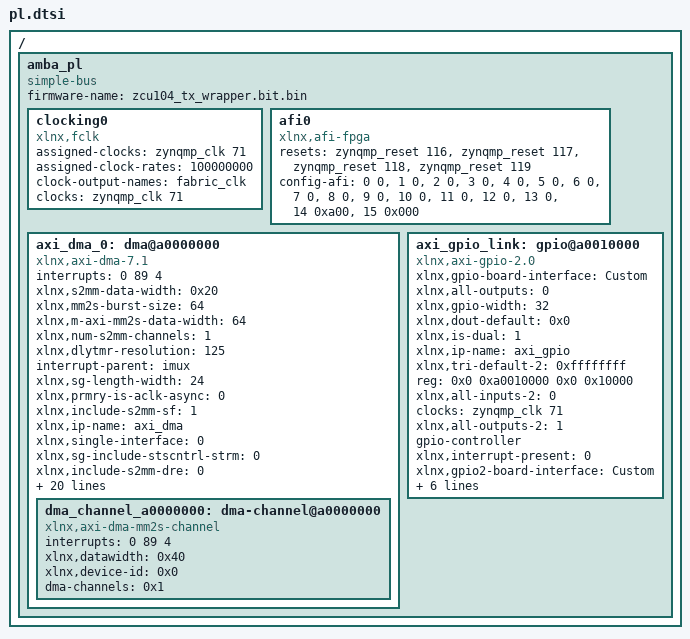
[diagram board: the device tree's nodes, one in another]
/ {
	amba_pl: amba_pl {
		ranges;
		compatible = "simple-bus";
		#address-cells = <2>;
		#size-cells = <2>;
		firmware-name = "zcu104_tx_wrapper.bit.bin";
		clocking0: clocking0 {
			compatible = "xlnx,fclk";
			status = "okay";
			assigned-clocks = <&zynqmp_clk 71>;
			assigned-clock-rates = <100000000>;
			#clock-cells = <0>;
			clock-output-names = "fabric_clk";
			clocks = <&zynqmp_clk 71>;
		};
		afi0: afi0 {
			status = "okay";
			compatible = "xlnx,afi-fpga";
			resets = <&zynqmp_reset 116>, <&zynqmp_reset 117>, <&zynqmp_reset 118>, <&zynqmp_reset 119>;
			config-afi = < 0 0>, <1 0>, <2 0>, <3 0>, <4 0>, <5 0>, <6 0>, <7 0>, <8 0>, <9 0>, <10 0>, <11 0>, <12 0>, <13 0>, <14 0xa00>, <15 0x000>;
		};
		axi_dma_0: dma@a0000000 {
			interrupts = < 0 89 4 >;
			compatible = "xlnx,axi-dma-7.1" , "xlnx,axi-dma-1.00.a";
			xlnx,s2mm-data-width = <0x20>;
			xlnx,mm2s-burst-size = <64>;
			xlnx,m-axi-mm2s-data-width = <64>;
			xlnx,num-s2mm-channels = <1>;
			xlnx,dlytmr-resolution = <125>;
			interrupt-parent = <&imux>;
			xlnx,sg-length-width = <24>;
			xlnx,prmry-is-aclk-async = <0>;
			xlnx,include-s2mm-sf = <1>;
			#dma-cells = <1>;
			xlnx,ip-name = "axi_dma";
			xlnx,single-interface = <0>;
			xlnx,sg-include-stscntrl-strm = <0>;
			xlnx,include-s2mm-dre = <0>;
			reg = <0x0 0xa0000000 0x0 0x10000>;
			xlnx,addr-width = <32>;
			xlnx,include-s2mm = <0>;
			clocks = <&zynqmp_clk 71>, <&zynqmp_clk 71>;
			xlnx,s-axis-s2mm-tdata-width = <32>;
			xlnx,micro-dma = <0>;
			xlnx,increase-throughput = <0>;
			xlnx,mm2s-data-width = <0x40>;
			xlnx,addrwidth = <0x20>;
			xlnx,sg-use-stsapp-length = <0>;
			xlnx,m-axis-mm2s-tdata-width = <32>;
			xlnx,edk-iptype = "PERIPHERAL";
			xlnx,s2mm-burst-size = <16>;
			xlnx,m-axi-s2mm-data-width = <32>;
			xlnx,num-mm2s-channels = <1>;
			xlnx,enable-multi-channel = <0>;
			status = "okay";
			xlnx,include-mm2s-sf = <1>;
			clock-names = "m_axi_mm2s_aclk" , "s_axi_lite_aclk";
			interrupt-names = "mm2s_introut";
			xlnx,include-mm2s = <1>;
			xlnx,include-mm2s-dre = <0>;
			xlnx,name = "axi_dma_0";
			dma_channel_a0000000: dma-channel@a0000000 {
				interrupts = <0 89 4>;
				xlnx,datawidth = <0x40>;
				xlnx,device-id = <0x0>;
				compatible = "xlnx,axi-dma-mm2s-channel";
				dma-channels = <0x1>;
			};
		};
		axi_gpio_link: gpio@a0010000 {
			xlnx,gpio-board-interface = "Custom";
			compatible = "xlnx,axi-gpio-2.0" , "xlnx,xps-gpio-1.00.a";
			xlnx,all-outputs = <0>;
			#gpio-cells = <2>;
			xlnx,gpio-width = <32>;
			xlnx,dout-default = <0x0>;
			xlnx,is-dual = <1>;
			xlnx,ip-name = "axi_gpio";
			xlnx,tri-default-2 = <0xffffffff>;
			reg = <0x0 0xa0010000 0x0 0x10000>;
			xlnx,all-inputs-2 = <0>;
			clocks = <&zynqmp_clk 71>;
			xlnx,all-outputs-2 = <1>;
			gpio-controller;
			xlnx,interrupt-present = <0>;
			xlnx,gpio2-board-interface = "Custom";
			xlnx,edk-iptype = "PERIPHERAL";
			xlnx,dout-default-2 = <0x1>;
			status = "okay";
			xlnx,gpio2-width = <32>;
			clock-names = "s_axi_aclk";
			xlnx,tri-default = <0xffffffff>;
			xlnx,name = "axi_gpio_link";
			xlnx,all-inputs = <1>;
		};
	};
};
